# CC2538SF53 register map
File version: 1
CPU: CM3 r2p1, little endian, no MPU, no FPU, 3 interrupt priority bits
Registers are 32-bit, read-write, reset 0x0 unless marked. A register's access mark holds for its fields unless they carry their own. Offsets are from the block's base; [hi:lo] are bit positions; {n}, {i} and the like mark numbered series.

## GPIO_A
Base 0x400D9000
0x00 DATA — This is the data register. In software control mode, values written in the GPIODATA register are transferred onto the GPOUT pins if the respective pins have been configured as outputs through the GPIODIR register. A read from GPIODATA returns the last bit value written if the respective pins are configured as output, or it returns the value on the corresponding input GPIN bit when these are configured as inputs.
  [7:0] DATA — Input and output data
0x400 DIR — The DIR register is the data direction register. All bits are cleared by a reset; therefore, the GPIO pins are input by default.
  [7:0] DIR — Bits set: Corresponding pin is output Bits cleared: Corresponding pin is input
0x404 IS — The IS register is the interrupt sense register.
  [7:0] IS — Bits set: Level on corresponding pin is detected Bits cleared: Edge on corresponding pin is detected
0x408 IBE — The IBE register is the interrupt both-edges register. When the corresponding bit in IS is set to detect edges, bits set to high in IBE configure the corresponding pin to detect both rising and falling edges, regardless of the corresponding bit in the IEV (interrupt event register). Clearing a bit configures the pin to be controlled by IEV.
  [7:0] IBE — Bits set: Both edges on corresponding pin trigger an interrupt Bits cleared: Interrupt generation event is controlled by GPIOIEV Single edge: Determined by corresponding bit in GPIOIEV register
0x40C IEV — The IEV register is the interrupt event register. Bits set to high in IEV configure the corresponding pin to detect rising edges or high levels, depending on the corresponding bit value in IS. Clearing a bit configures the pin to detect falling edges or low levels, depending on the corresponding bit value in IS.
  [7:0] IEV — Bits set: Rising edges or high levels on corresponding pin trigger interrupts Bits cleared: Falling edges or low levels on corresponding pin trigger interrupts
0x410 IE — The IE register is the interrupt mask register. Bits set to high in IE allow the corresponding pins to trigger their individual interrupts and the combined GPIOINTR line. Clearing a bit disables interrupt triggering on that pin.
  [7:0] IE — Bits set: Corresponding pin is not masked Bits cleared: Corresponding pin is masked
0x414 RIS ro — The RIS register is the raw interrupt status register. Bits read high in RIS reflect the status of interrupts trigger conditions detected (raw, before masking), indicating that all the requirements are met, before they are finally allowed to trigger by IE. Bits read as 0 indicate that corresponding input pins have not initiated an interrupt.
  [7:0] RIS — Reflects the status of interrupts trigger conditions detected on pins (raw, before masking) Bits set: Requirements met by corresponding pins Bits clear: Requirements not met
0x418 MIS ro — The MIS register is the masked interrupt status register. Bits read high in MIS reflect the status of input lines triggering an interrupt. Bits read as low indicate that either no interrupt has been generated, or the interrupt is masked. MIS is the state of the interrupt after masking.
  [7:0] MIS — Masked value of interrupt due to corresponding pin Bits clear: GPIO line interrupt not active Bits set: GPIO line asserting interrupt
0x41C IC wo — The IC register is the interrupt clear register. Writing 1 to a bit in this register clears the corresponding interrupt edge detection logic register. Writing 0 has no effect.
  [7:0] IC — Bit written as 1: Clears edge detection logic Bit written as 0: Has no effect
0x420 AFSEL — The AFSEL register is the mode control select register. Writing 1 to any bit in this register selects the hardware (peripheral) control for the corresponding GPIO line. All bits are cleared by a reset, therefore no GPIO line is set to hardware control by default.
  [7:0] AFSEL — Bit set: Enables hardware (peripheral) control mode Bit cleared: Enables software control mode
0x520 GPIOLOCK reset 0x1 — A write of the value 0x4C4F434B to the GPIOLOCK register unlocks the GPIO commit register (GPIOCR) for write access. A write of any other value reapplies the lock, preventing any register updates. Any write to the commit register (GPIOCR) causes the lock register to be locked.
  [31:0] LOCK — A read of this register returns the following values: Locked: 0x00000001 Unlocked: 0x00000000
0x524 GPIOCR reset 0xFF — The GPIOCR register is the commit register. The value of the GPIOCR register determines which bits of the AFSEL register is committed when a write to the AFSEL register is performed. If a bit in the GPIOCR register is 0, the data being written to the corresponding bit in the AFSEL register is not committed and retains its previous value. If a bit in the GPIOCR register is set to 1, the data being written to the corresponding bit of the AFSEL register is committed to the register and will reflect the new value. The contents of the GPIOCR register can only be modified if the GPIOLOCK register is unlocked. Writes to the GPIOCR register will be ignored if the GPIOLOCK register is locked. Any write to the commit register causes the lock register to be locked.
  [7:0] CR — On a bit-wise basis, any bit set allows the corresponding GPIOAFSEL bit to be set to its alternate function.
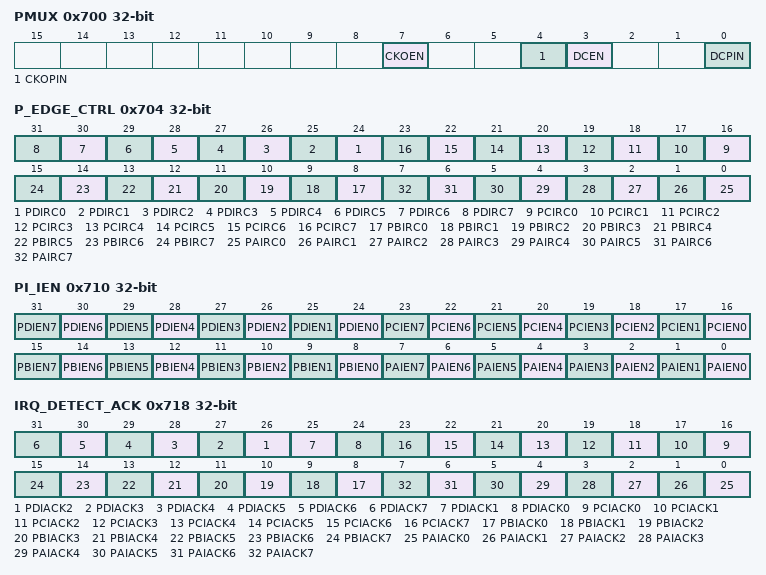
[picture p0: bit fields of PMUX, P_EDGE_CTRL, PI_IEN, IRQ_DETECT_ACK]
0x700 PMUX — The PMUX register can be used to output external decouple control and clock_32k on I/O pins. Decouple control can be output on specific PB pins and clock_32k can be output on a specific PA or PB pin. These features override the current setting of the selected pin when enabled. The pin is set to output, pull-up and -down disabled, and analog mode disabled.
  [7] CKOEN — Clock out enable When this bit is set, the 32-kHz clock is routed to either PA[0] or PB[7] pins. PMUX.CKOPIN selects the pin to use. This overrides the current configuration setting for this pin. The pullup or pulldown is disabled and the direction is set to output for this pin.
  [4] CKOPIN — Decouple control pin select This control only has relevance when CKOEN is set. When 0, PA[0] becomes the 32-kHz clock output. When 1, PB[7] becomes the 32-kHz clock output.
  [3] DCEN — Decouple control enable When this bit is set, the on-die digital regulator status is routed to either PB[1] or PB[0] pins. PMUX.DCPIN selects the pin to use. This overrides the current configuration setting for this pin. The pullup or pulldown is disabled and the direction is set to output for this pin.
  [0] DCPIN — Decouple control pin select This control has relevance only when DCEN is set. When 0, PB[1] becomes the on-die digital regulator status (1 indicates the on-die digital regulator is active); when 1, PB[0] becomes the on-die digital regulator status. NOTE: PB[1] and PB[0] can also be controlled with other override features. In priority order for PB[1]: When POR/BOD test mode is active, PB[1] becomes the active low brown-out detected indicator. When DCEN is set and DCPIN is not set, PB[1] becomes the on-dir digital regulator status. In priority order for PB[0]: When POR/BOD test mode is active, PB[0] becomes the power-on-reset indicator. When DCEN and DCPIN are set, PB[0] becomes the on-die digital regulator status.
0x704 P_EDGE_CTRL — The port edge control register is used to control which edge of each port input causes that port to generate a power-up interrupt to the system.
  [n+24] PDIRC{n} (n=0..7) — Port D bit {n} interrupt request condition: 0: Rising 1: Falling edge
  [n+16] PCIRC{n} (n=0..7) — Port C bit {n} interrupt request condition: 0: Rising 1: Falling edge
  [n+8] PBIRC{n} (n=0..7) — Port B bit {n} interrupt request condition: 0: Rising 1: Falling edge
  [n] PAIRC{n} (n=0..7) — Port A bit {n} interrupt request condition: 0: Rising 1: Falling edge
0x708 USB_CTRL — This register is used to control which edge of the USB controller input generates a power-up interrupt to the system.
  [0] USB_EDGE_CTL — Used to set the edge which triggers the USB power up interrupt 0: Rising 1: Falling
0x710 PI_IEN — The power-up interrupt enable register selects, for its corresponding port A-D pin, whether interrupts are enabled or disabled.
  [n+24] PDIEN{n} (n=0..7) — Port D bit {n} interrupt enable: 1: Enabled 2: Disabled
  [n+16] PCIEN{n} (n=0..7) — Port C bit {n} interrupt enable: 1: Enabled 2: Disabled
  [n+8] PBIEN{n} (n=0..7) — Port B bit {n} interrupt enable: 1: Enabled 2: Disabled
  [n] PAIEN{n} (n=0..7) — Port A bit {n} interrupt enable: 1: Enabled 2: Disabled
0x718 IRQ_DETECT_ACK — If the IRQ detect ACK register is read, the value returned can be used to determine which enabled I/O port is responsible for creating a power-up interrupt to the system. Writing the IRQ detect ACK register is used to clear any number of individual port bits that may be signaling that an edge was detected as configured by the port edge control register and the interrupt control register. There is a self-clearing function to this register that generates a reset pulse to clear any interrupt which has its corresponding bit set to 1.
  [n+24] PDIACK{n} (n=2..7) — Port D bit {n} masked interrupt status: 1: Detected 0: Not detected
  [25] PDIACK1 — Port D bit 1 masked interrupt status: 1: Detected0: Not detected
  [24] PDIACK0 — Port D bit 0 masked interrupt status: 1: Detected 0: Not detected
  [n+16] PCIACK{n} (n=0..7) — Port C bit {n} masked interrupt status: 1: Detected 0: Not detected
  [n+8] PBIACK{n} (n=0..7) — Port B bit {n} masked interrupt status: 1: Detected 0: Not detected
  [n] PAIACK{n} (n=0..7) — Port A bit {n} masked interrupt status: 1: Detected 0: Not detected
0x71C USB_IRQ_ACK — Same functionality as IRQ_DETECT_ACK, but for USB
  [0] USBACK — USB masked interrupt status: 1: Detected 0: Not detected
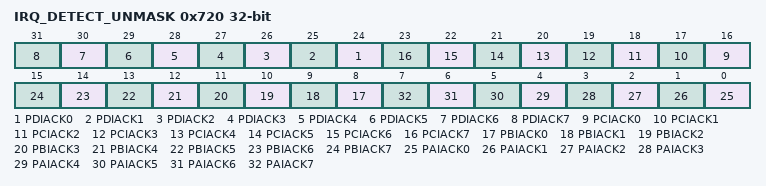
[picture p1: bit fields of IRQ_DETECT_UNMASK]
0x720 IRQ_DETECT_UNMASK — Same functionality as IRQ_DETECT_ACK, but this register handles masked interrupts
  [n+24] PDIACK{n} (n=0..7) — Port D bit {n} unmasked interrupt status: 1: Detected 0: Undetected
  [n+16] PCIACK{n} (n=0..7) — Port C bit {n} unmasked interrupt status: 1: Detected 0: Undetected
  [n+8] PBIACK{n} (n=0..7) — Port B bit {n} unmasked interrupt status: 1: Detected 0: Undetected
  [n] PAIACK{n} (n=0..7) — Port A bit {n} unmasked interrupt status: 1: Detected 0: Undetected

## GPIO_B
Base 0x400DA000
Same registers: GPIO_C 0x400DB000, GPIO_D 0x400DC000
Registers as GPIO_A; these are added or differ:
0x520 GPIOLOCK — A write of the value 0x4C4F434B to the GPIOLOCK register unlocks the GPIO commit register (GPIOCR) for write access. A write of any other value reapplies the lock, preventing any register updates. Any write to the commit register (GPIOCR) causes the lock register to be locked.
  [31:0] LOCK — A read of this register returns the following values: Locked: 0x00000001 Unlocked: 0x00000000
0x524 GPIOCR — The GPIOCR register is the commit register. The value of the GPIOCR register determines which bits of the AFSEL register is committed when a write to the AFSEL register is performed. If a bit in the GPIOCR register is 0, the data being written to the corresponding bit in the AFSEL register is not committed and retains its previous value. If a bit in the GPIOCR register is set to 1, the data being written to the corresponding bit of the AFSEL register is committed to the register and will reflect the new value. The contents of the GPIOCR register can only be modified if the GPIOLOCK register is unlocked. Writes to the GPIOCR register will be ignored if the GPIOLOCK register is locked. Any write to the commit register causes the lock register to be locked.
  [7:0] CR — On a bit-wise basis, any bit set allows the corresponding GPIOAFSEL bit to be set to its alternate function.
